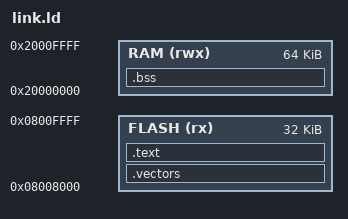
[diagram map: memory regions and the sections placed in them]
/* SPDX-License-Identifier: BSD-3-Clause
 * Copyright (c) 2026 Brickwright contributors */
ENTRY(reset_handler)
MEMORY { FLASH (rx) : ORIGIN = 0x08008000, LENGTH = 32K
         RAM (rwx) : ORIGIN = 0x20000000, LENGTH = 64K }
SECTIONS {
    .vectors : { KEEP(*(.vectors)) } > FLASH
    .text : { *(.text*) *(.rodata*) } > FLASH
    .bss (NOLOAD) : { __bss_start__ = .; *(.bss*) *(COMMON) __bss_end__ = .; } > RAM
    /DISCARD/ : { *(.comment) *(.ARM.exidx*) *(.ARM.extab*) }
}
